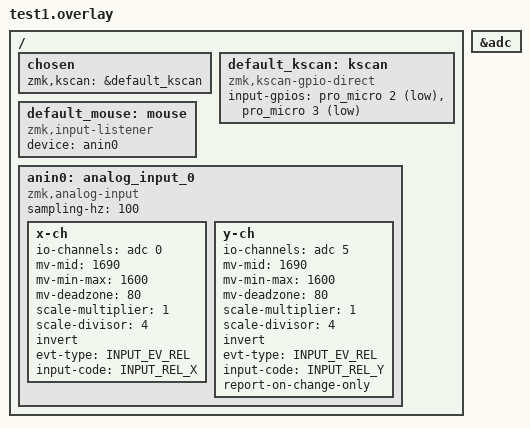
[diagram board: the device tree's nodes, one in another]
#include <zephyr/dt-bindings/input/input-event-codes.h>
/* Reference: https://docs.zephyrproject.org/apidoc/latest/group__input__events.html */

&adc {
	status = "okay";
};

/ {
    chosen {
        zmk,kscan = &default_kscan;
    };

    default_kscan: kscan {
        compatible = "zmk,kscan-gpio-direct";

        input-gpios =
            <&pro_micro 2 (GPIO_ACTIVE_LOW | GPIO_PULL_UP)>,
            <&pro_micro 3 (GPIO_ACTIVE_LOW | GPIO_PULL_UP)>;
    };

	// MOUSE CONFIGURATION - Try this simpler version first
    default_mouse: mouse {
        compatible = "zmk,input-listener";
        device = <&anin0>;
        
    };

	anin0: analog_input_0 {
		compatible = "zmk,analog-input";

		sampling-hz = <100>;
		x-ch {
			io-channels = <&adc 0>; // <--- see ain-map.png for nRF52840
			mv-mid = <1690>;         // Center voltage (neutral joystick position)
    		mv-min-max = <1600>;     // Range around center considered valid
    		mv-deadzone = <80>;      // Ignore values ±10 mV around mv-mid
			scale-multiplier = <1>;
			scale-divisor = <4>;  // Scale to HID step size
			invert;
			evt-type = <INPUT_EV_REL>; // Relative movement (like mouse)
			input-code = <INPUT_REL_X>; // Horizontal axis (X)
		};
		y-ch {
			io-channels = <&adc 5>; // <--- see ain-map.png for nRF52840
			mv-mid = <1690>;
			mv-min-max = <1600>;
			mv-deadzone = <80>;
			scale-multiplier = <1>;
			scale-divisor = <4>;
			invert;
			evt-type = <INPUT_EV_REL>;
			input-code = <INPUT_REL_Y>;

			/* enable report mdoe for gamepad axix or knob */
			/* to only call input_report on quantquantized value is updated */
			/* NOTE: mouse input does NOT need this */
			report-on-change-only;

		};
	};
};
